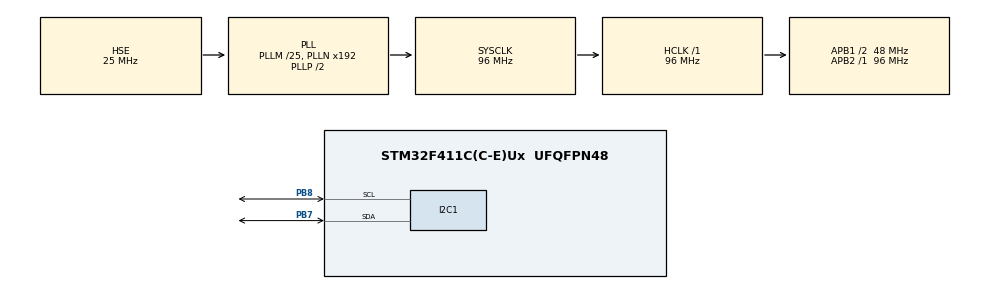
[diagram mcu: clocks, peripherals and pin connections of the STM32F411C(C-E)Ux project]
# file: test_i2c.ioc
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Dma.I2C1_RX.0.Direction=DMA_PERIPH_TO_MEMORY
Dma.I2C1_RX.0.FIFOMode=DMA_FIFOMODE_DISABLE
Dma.I2C1_RX.0.Instance=DMA1_Stream5
Dma.I2C1_RX.0.MemDataAlignment=DMA_MDATAALIGN_BYTE
Dma.I2C1_RX.0.MemInc=DMA_MINC_ENABLE
Dma.I2C1_RX.0.Mode=DMA_CIRCULAR
Dma.I2C1_RX.0.PeriphDataAlignment=DMA_PDATAALIGN_BYTE
Dma.I2C1_RX.0.PeriphInc=DMA_PINC_DISABLE
Dma.I2C1_RX.0.Priority=DMA_PRIORITY_LOW
Dma.I2C1_TX.1.Direction=DMA_MEMORY_TO_PERIPH
Dma.I2C1_TX.1.FIFOMode=DMA_FIFOMODE_DISABLE
Dma.I2C1_TX.1.Instance=DMA1_Stream6
Dma.I2C1_TX.1.MemDataAlignment=DMA_MDATAALIGN_BYTE
Dma.I2C1_TX.1.MemInc=DMA_MINC_ENABLE
Dma.I2C1_TX.1.Mode=DMA_CIRCULAR
Dma.I2C1_TX.1.PeriphDataAlignment=DMA_PDATAALIGN_BYTE
Dma.I2C1_TX.1.PeriphInc=DMA_PINC_DISABLE
Dma.I2C1_TX.1.Priority=DMA_PRIORITY_LOW
Dma.Request0=I2C1_RX
Dma.Request1=I2C1_TX
I2C1.DutyCycle=I2C_DUTYCYCLE_16_9
I2C1.I2C_Mode=I2C_Fast
Mcu.Family=STM32F4
Mcu.Name=STM32F411C(C-E)Ux
Mcu.Package=UFQFPN48
NVIC.DMA1_Stream5_IRQn=true\:0\:0\:false\:false\:true\:false\:true\:true
NVIC.DMA1_Stream6_IRQn=true\:0\:0\:false\:false\:true\:false\:true\:true
NVIC.I2C1_ER_IRQn=true\:0\:0\:false\:false\:true\:true\:true\:true
NVIC.I2C1_EV_IRQn=true\:0\:0\:false\:false\:true\:true\:true\:true
NVIC.PriorityGroup=NVIC_PRIORITYGROUP_4
PA13.Mode=Serial_Wire
PA13.Signal=SYS_JTMS-SWDIO
PA14.Mode=Serial_Wire
PA14.Signal=SYS_JTCK-SWCLK
PB7.Mode=I2C
PB7.Signal=I2C1_SDA
PB8.Mode=I2C
PB8.Signal=I2C1_SCL
PH0\ -\ OSC_IN.Mode=HSE-External-Oscillator
PH0\ -\ OSC_IN.Signal=RCC_OSC_IN
PH1\ -\ OSC_OUT.Mode=HSE-External-Oscillator
PH1\ -\ OSC_OUT.Signal=RCC_OSC_OUT
ProjectManager.HeapSize=0x200
ProjectManager.StackSize=0x400
ProjectManager.TargetToolchain=STM32CubeIDE
RCC.48MHZClocksFreq_Value=48000000
RCC.AHBFreq_Value=96000000
RCC.APB1CLKDivider=RCC_HCLK_DIV2
RCC.APB1Freq_Value=48000000
RCC.APB1TimFreq_Value=96000000
RCC.APB2Freq_Value=96000000
RCC.APB2TimFreq_Value=96000000
RCC.CortexFreq_Value=96000000
RCC.HCLKFreq_Value=96000000
RCC.HSE_VALUE=25000000
RCC.HSI_VALUE=16000000
RCC.LSE_VALUE=32768
RCC.PLLM=25
RCC.PLLSourceVirtual=RCC_PLLSOURCE_HSE
RCC.SYSCLKFreq_VALUE=96000000
RCC.SYSCLKSource=RCC_SYSCLKSOURCE_PLLCLK
RCC.VCOOutputFreq_Value=192000000
board=custom

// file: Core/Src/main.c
/* USER CODE BEGIN Header */
/**
 ******************************************************************************
 * @file           : main.c
 * @brief          : Main program body
 ******************************************************************************
 * @attention
 *
 * Copyright (c) 2023 STMicroelectronics.
 * All rights reserved.
 *
 * This software is licensed under terms that can be found in the LICENSE file
 * in the root directory of this software component.
 * If no LICENSE file comes with this software, it is provided AS-IS.
 *
 ******************************************************************************
 */
/* USER CODE END Header */
#include "main.h"
#include "dma.h"
#include "i2c.h"
#include "gpio.h"
#include "string.h"

/* USER CODE BEGIN PV */
volatile HAL_StatusTypeDef halStatus;
/* USER CODE END PV */

void SystemClock_Config(void);

/* USER CODE BEGIN 0 */
volatile uint8_t readCplt = 0;
volatile uint8_t writeCplt = 0;
void HAL_I2C_MemRxCpltCallback(I2C_HandleTypeDef *hi2c) {
	// https://community.st.com/t5/stm32cubemx-mcu/why-hal-dma-functions-are-not-working/td-p/400261
	// Add HAL_DMA_Abort_IT(hi2c->hdmarx) at interrupt, Otherwise dmaxferstatus = HAL_DMA_Start_IT() in HAL_I2C_Mem_Read_DMA will return busy
	if (hi2c->Instance == hi2c1.Instance) {
		HAL_DMA_Abort_IT(hi2c->hdmarx);

	}
	readCplt = 1;
}
void HAL_I2C_MemTxCpltCallback(I2C_HandleTypeDef *hi2c) {
	// https://community.st.com/t5/stm32cubemx-mcu/why-hal-dma-functions-are-not-working/td-p/400261
	// Add HAL_DMA_Abort_IT(hi2c->hdmatx) at interrupt, Otherwise dmaxferstatus = HAL_DMA_Start_IT() in HAL_I2C_Mem_Write_DMA will return busy
	if (hi2c->Instance == hi2c1.Instance) {
		HAL_DMA_Abort_IT(hi2c->hdmatx);

	}
	writeCplt = 1;
}
/* USER CODE END 0 */

int main(void)
{

  /* MCU Configuration--------------------------------------------------------*/

  /* Reset of all peripherals, Initializes the Flash interface and the Systick. */
  HAL_Init();

  /* Configure the system clock */
  SystemClock_Config();

  /* Initialize all configured peripherals */
  MX_GPIO_Init();
  MX_DMA_Init();
  MX_I2C1_Init();
  /* USER CODE BEGIN 2 */

	uint8_t rxData[16];
	uint8_t txData[16];

	// erase AT24C02
	memset(txData, 00, 16);
	HAL_I2C_Mem_Write_DMA(&hi2c1, 0xa0, 0, I2C_MEMADD_SIZE_8BIT, txData, 16);
	HAL_Delay(1000);
	// Read 16 bytes
	readCplt = 0;
	halStatus = HAL_I2C_Mem_Read_DMA(&hi2c1, 0xA0, 0, I2C_MEMADD_SIZE_8BIT,
			rxData, 16);
	HAL_Delay(1000);

	// Write two bytes @ address 0 to AT24C02
	writeCplt = 0;
	txData[0] = 0xAA;
	txData[1] = 0xBB;
	HAL_I2C_Mem_Write_DMA(&hi2c1, 0xa0, 0, I2C_MEMADD_SIZE_8BIT, txData, 2);
	HAL_Delay(1000);
	// Read 16 bytes
	readCplt = 0;
	halStatus = HAL_I2C_Mem_Read_DMA(&hi2c1, 0xA0, 0, I2C_MEMADD_SIZE_8BIT,
			rxData, 16);
	HAL_Delay(1000);

	// Write two bytes @ address 2 to AT24C02
	writeCplt = 0;
	txData[0] = 0xCC;
	txData[1] = 0xDD;
	HAL_I2C_Mem_Write_DMA(&hi2c1, 0xa0, 2, I2C_MEMADD_SIZE_8BIT, txData, 2);
	HAL_Delay(1000);
	// Read 16 bytes
	readCplt = 0;
	halStatus = HAL_I2C_Mem_Read_DMA(&hi2c1, 0xA0, 0, I2C_MEMADD_SIZE_8BIT,
			rxData, 16);
	HAL_Delay(1000);

  /* USER CODE END 2 */

  /* Infinite loop */
	while (1) {

	}
}

void SystemClock_Config(void)
{
  RCC_OscInitTypeDef RCC_OscInitStruct = {0};
  RCC_ClkInitTypeDef RCC_ClkInitStruct = {0};

  /** Configure the main internal regulator output voltage
  */
  __HAL_RCC_PWR_CLK_ENABLE();
  __HAL_PWR_VOLTAGESCALING_CONFIG(PWR_REGULATOR_VOLTAGE_SCALE1);

  /** Initializes the RCC Oscillators according to the specified parameters
  * in the RCC_OscInitTypeDef structure.
  */
  RCC_OscInitStruct.OscillatorType = RCC_OSCILLATORTYPE_HSE;
  RCC_OscInitStruct.HSEState = RCC_HSE_ON;
  RCC_OscInitStruct.PLL.PLLState = RCC_PLL_ON;
  RCC_OscInitStruct.PLL.PLLSource = RCC_PLLSOURCE_HSE;
  RCC_OscInitStruct.PLL.PLLM = 25;
  RCC_OscInitStruct.PLL.PLLN = 192;
  RCC_OscInitStruct.PLL.PLLP = RCC_PLLP_DIV2;
  RCC_OscInitStruct.PLL.PLLQ = 4;
  if (HAL_RCC_OscConfig(&RCC_OscInitStruct) != HAL_OK)
  {
    Error_Handler();
  }

  /** Initializes the CPU, AHB and APB buses clocks
  */
  RCC_ClkInitStruct.ClockType = RCC_CLOCKTYPE_HCLK|RCC_CLOCKTYPE_SYSCLK
                              |RCC_CLOCKTYPE_PCLK1|RCC_CLOCKTYPE_PCLK2;
  RCC_ClkInitStruct.SYSCLKSource = RCC_SYSCLKSOURCE_PLLCLK;
  RCC_ClkInitStruct.AHBCLKDivider = RCC_SYSCLK_DIV1;
  RCC_ClkInitStruct.APB1CLKDivider = RCC_HCLK_DIV2;
  RCC_ClkInitStruct.APB2CLKDivider = RCC_HCLK_DIV1;

  if (HAL_RCC_ClockConfig(&RCC_ClkInitStruct, FLASH_LATENCY_3) != HAL_OK)
  {
    Error_Handler();
  }
}

void Error_Handler(void)
{
	__disable_irq();
	while (1) {
	}
}
